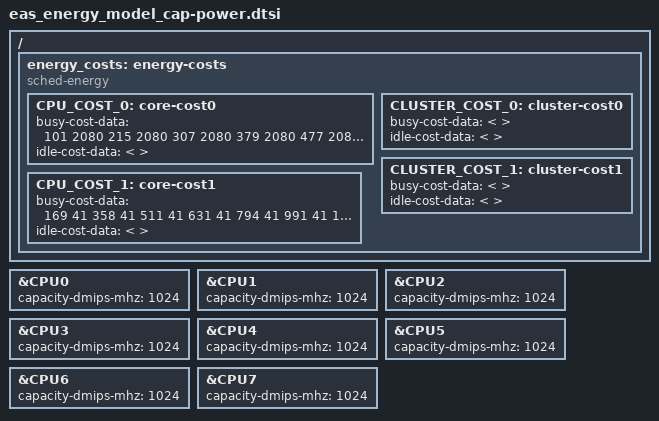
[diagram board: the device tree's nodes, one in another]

&CPU0 {
	capacity-dmips-mhz = <1024>;
};

&CPU1 {
	capacity-dmips-mhz = <1024>;
};

&CPU2 {
	capacity-dmips-mhz = <1024>;
};

&CPU3 {
	capacity-dmips-mhz = <1024>;
};

&CPU4 {
	capacity-dmips-mhz = <1024>;
};

&CPU5 {
	capacity-dmips-mhz = <1024>;
};

&CPU6 {
	capacity-dmips-mhz = <1024>;
};

&CPU7 {
	capacity-dmips-mhz = <1024>;
};

/ {
	energy_costs: energy-costs {
		compatible = "sched-energy";

		CPU_COST_0: core-cost0 {
			busy-cost-data = <
				 101 2080
				 215 2080
				 307 2080
				 379 2080
				 477 2080
				 523 2080
				 549 2080
			>;
			idle-cost-data = <
				
			>;
		};

		CPU_COST_1: core-cost1 {
			busy-cost-data = <
				 169   41
				 358   41
				 511   41
				 631   41
				 794   41
				 991   41
				1024   41
			>;
			idle-cost-data = <
				
			>;
		};

		CLUSTER_COST_0: cluster-cost0 {
			busy-cost-data = <
			>;
			idle-cost-data = <
				
			>;
		};

		CLUSTER_COST_1: cluster-cost1 {
			busy-cost-data = <
			>;
			idle-cost-data = <
				
			>;
		};
	}; /* energy-costs */
};
